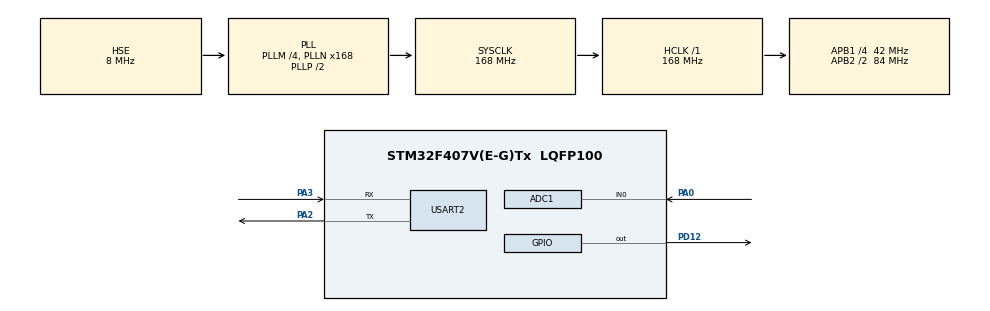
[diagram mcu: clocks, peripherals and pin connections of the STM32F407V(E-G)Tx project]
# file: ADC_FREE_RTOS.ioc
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ADC1.Channel-0\#ChannelRegularConversion=ADC_CHANNEL_0
ADC1.ClockPrescaler=ADC_CLOCK_SYNC_PCLK_DIV4
ADC1.NbrOfConversionFlag=1
ADC1.Rank-0\#ChannelRegularConversion=1
ADC1.Resolution=ADC_RESOLUTION_8B
ADC1.SamplingTime-0\#ChannelRegularConversion=ADC_SAMPLETIME_28CYCLES
ADC1.master=1
FREERTOS.BinarySemaphores01=BinSem,Dynamic,NULL
FREERTOS.Tasks01=LEDTask,0,128,LEDtask,Default,NULL,Dynamic,NULL,NULL;myADC,1,128,ADCTask,Default,NULL,Dynamic,NULL,NULL
Mcu.Family=STM32F4
Mcu.Name=STM32F407V(E-G)Tx
Mcu.Package=LQFP100
NVIC.PriorityGroup=NVIC_PRIORITYGROUP_4
NVIC.TIM1_UP_TIM10_IRQn=true\:0\:0\:false\:false\:true\:false\:false\:true
NVIC.TimeBase=TIM1_UP_TIM10_IRQn
NVIC.TimeBaseIP=TIM1
PA0-WKUP.Signal=ADCx_IN0
PA2.Mode=Asynchronous
PA2.Signal=USART2_TX
PA3.Mode=Asynchronous
PA3.Signal=USART2_RX
PD12.Signal=GPIO_Output
PH0-OSC_IN.Mode=HSE-External-Oscillator
PH0-OSC_IN.Signal=RCC_OSC_IN
PH1-OSC_OUT.Mode=HSE-External-Oscillator
PH1-OSC_OUT.Signal=RCC_OSC_OUT
ProjectManager.HeapSize=0x200
ProjectManager.StackSize=0x400
ProjectManager.TargetToolchain=STM32CubeIDE
RCC.48MHZClocksFreq_Value=84000000
RCC.AHBFreq_Value=168000000
RCC.APB1CLKDivider=RCC_HCLK_DIV4
RCC.APB1Freq_Value=42000000
RCC.APB1TimFreq_Value=84000000
RCC.APB2CLKDivider=RCC_HCLK_DIV2
RCC.APB2Freq_Value=84000000
RCC.APB2TimFreq_Value=168000000
RCC.CortexFreq_Value=168000000
RCC.HCLKFreq_Value=168000000
RCC.HSE_VALUE=8000000
RCC.HSI_VALUE=16000000
RCC.LSE_VALUE=32768
RCC.PLLM=4
RCC.PLLN=168
RCC.PLLSourceVirtual=RCC_PLLSOURCE_HSE
RCC.SYSCLKFreq_VALUE=168000000
RCC.SYSCLKSource=RCC_SYSCLKSOURCE_PLLCLK
RCC.VCOOutputFreq_Value=336000000
SH.ADCx_IN0.0=ADC1_IN0,IN0
USART2.VirtualMode=VM_ASYNC
VP_FREERTOS_VS_CMSIS_V1.Mode=CMSIS_V1
VP_SYS_VS_tim1.Mode=TIM1
board=custom

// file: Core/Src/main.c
/* USER CODE BEGIN Header */
/**
  ******************************************************************************
  * @file           : main.c
  * @brief          : Main program body
  ******************************************************************************
  * @attention
  *
  * <h2><center>&copy; Copyright (c) 2021 STMicroelectronics.
  * All rights reserved.</center></h2>
  *
  * This software component is licensed by ST under BSD 3-Clause license,
  * the "License"; You may not use this file except in compliance with the
  * License. You may obtain a copy of the License at:
  *                        opensource.org/licenses/BSD-3-Clause
  *
  ******************************************************************************
  */
/* USER CODE END Header */
#include "main.h"
#include "cmsis_os.h"

ADC_HandleTypeDef hadc1;

UART_HandleTypeDef huart2;

osThreadId LEDTaskHandle;
osThreadId myADCHandle;
osSemaphoreId BinSemHandle;

void SystemClock_Config(void);
static void MX_GPIO_Init(void);
static void MX_ADC1_Init(void);
static void MX_USART2_UART_Init(void);
void LEDtask(void const * argument);
void ADCTask(void const * argument);

/* USER CODE BEGIN PFP */
uint32_t adcVal0;
/* USER CODE END PFP */

int main(void)
{

  /* MCU Configuration--------------------------------------------------------*/

  /* Reset of all peripherals, Initializes the Flash interface and the Systick. */
  HAL_Init();

  /* Configure the system clock */
  SystemClock_Config();

  /* Initialize all configured peripherals */
  MX_GPIO_Init();
  MX_ADC1_Init();
  MX_USART2_UART_Init();

  /* Create the semaphores(s) */
  /* definition and creation of BinSem */
  osSemaphoreDef(BinSem);
  BinSemHandle = osSemaphoreCreate(osSemaphore(BinSem), 1);

  /* Create the thread(s) */
  /* definition and creation of LEDTask */
  osThreadDef(LEDTask, LEDtask, osPriorityNormal, 0, 128);
  LEDTaskHandle = osThreadCreate(osThread(LEDTask), NULL);

  /* definition and creation of myADC */
  osThreadDef(myADC, ADCTask, osPriorityAboveNormal, 0, 128);
  myADCHandle = osThreadCreate(osThread(myADC), NULL);

  /* Start scheduler */
  osKernelStart();

  /* We should never get here as control is now taken by the scheduler */
  /* Infinite loop */
  while (1)
  {

  }
}

void SystemClock_Config(void)
{
  RCC_OscInitTypeDef RCC_OscInitStruct = {0};
  RCC_ClkInitTypeDef RCC_ClkInitStruct = {0};

  /** Configure the main internal regulator output voltage
  */
  __HAL_RCC_PWR_CLK_ENABLE();
  __HAL_PWR_VOLTAGESCALING_CONFIG(PWR_REGULATOR_VOLTAGE_SCALE1);
  /** Initializes the RCC Oscillators according to the specified parameters
  * in the RCC_OscInitTypeDef structure.
  */
  RCC_OscInitStruct.OscillatorType = RCC_OSCILLATORTYPE_HSE;
  RCC_OscInitStruct.HSEState = RCC_HSE_ON;
  RCC_OscInitStruct.PLL.PLLState = RCC_PLL_ON;
  RCC_OscInitStruct.PLL.PLLSource = RCC_PLLSOURCE_HSE;
  RCC_OscInitStruct.PLL.PLLM = 4;
  RCC_OscInitStruct.PLL.PLLN = 168;
  RCC_OscInitStruct.PLL.PLLP = RCC_PLLP_DIV2;
  RCC_OscInitStruct.PLL.PLLQ = 4;
  if (HAL_RCC_OscConfig(&RCC_OscInitStruct) != HAL_OK)
  {
    Error_Handler();
  }
  /** Initializes the CPU, AHB and APB buses clocks
  */
  RCC_ClkInitStruct.ClockType = RCC_CLOCKTYPE_HCLK|RCC_CLOCKTYPE_SYSCLK
                              |RCC_CLOCKTYPE_PCLK1|RCC_CLOCKTYPE_PCLK2;
  RCC_ClkInitStruct.SYSCLKSource = RCC_SYSCLKSOURCE_PLLCLK;
  RCC_ClkInitStruct.AHBCLKDivider = RCC_SYSCLK_DIV1;
  RCC_ClkInitStruct.APB1CLKDivider = RCC_HCLK_DIV4;
  RCC_ClkInitStruct.APB2CLKDivider = RCC_HCLK_DIV2;

  if (HAL_RCC_ClockConfig(&RCC_ClkInitStruct, FLASH_LATENCY_5) != HAL_OK)
  {
    Error_Handler();
  }
}

static void MX_ADC1_Init(void)
{

  ADC_ChannelConfTypeDef sConfig = {0};

  /** Configure the global features of the ADC (Clock, Resolution, Data Alignment and number of conversion)
  */
  hadc1.Instance = ADC1;
  hadc1.Init.ClockPrescaler = ADC_CLOCK_SYNC_PCLK_DIV4;
  hadc1.Init.Resolution = ADC_RESOLUTION_8B;
  hadc1.Init.ScanConvMode = DISABLE;
  hadc1.Init.ContinuousConvMode = DISABLE;
  hadc1.Init.DiscontinuousConvMode = DISABLE;
  hadc1.Init.ExternalTrigConvEdge = ADC_EXTERNALTRIGCONVEDGE_NONE;
  hadc1.Init.ExternalTrigConv = ADC_SOFTWARE_START;
  hadc1.Init.DataAlign = ADC_DATAALIGN_RIGHT;
  hadc1.Init.NbrOfConversion = 1;
  hadc1.Init.DMAContinuousRequests = DISABLE;
  hadc1.Init.EOCSelection = ADC_EOC_SINGLE_CONV;
  if (HAL_ADC_Init(&hadc1) != HAL_OK)
  {
    Error_Handler();
  }
  /** Configure for the selected ADC regular channel its corresponding rank in the sequencer and its sample time.
  */
  sConfig.Channel = ADC_CHANNEL_0;
  sConfig.Rank = 1;
  sConfig.SamplingTime = ADC_SAMPLETIME_28CYCLES;
  if (HAL_ADC_ConfigChannel(&hadc1, &sConfig) != HAL_OK)
  {
    Error_Handler();
  }

}

static void MX_USART2_UART_Init(void)
{

  huart2.Instance = USART2;
  huart2.Init.BaudRate = 115200;
  huart2.Init.WordLength = UART_WORDLENGTH_8B;
  huart2.Init.StopBits = UART_STOPBITS_1;
  huart2.Init.Parity = UART_PARITY_NONE;
  huart2.Init.Mode = UART_MODE_TX_RX;
  huart2.Init.HwFlowCtl = UART_HWCONTROL_NONE;
  huart2.Init.OverSampling = UART_OVERSAMPLING_16;
  if (HAL_UART_Init(&huart2) != HAL_OK)
  {
    Error_Handler();
  }

}

static void MX_GPIO_Init(void)
{
  GPIO_InitTypeDef GPIO_InitStruct = {0};

  /* GPIO Ports Clock Enable */
  __HAL_RCC_GPIOH_CLK_ENABLE();
  __HAL_RCC_GPIOA_CLK_ENABLE();
  __HAL_RCC_GPIOD_CLK_ENABLE();

  /*Configure GPIO pin Output Level */
  HAL_GPIO_WritePin(GPIOD, GPIO_PIN_12, GPIO_PIN_RESET);

  /*Configure GPIO pin : PD12 */
  GPIO_InitStruct.Pin = GPIO_PIN_12;
  GPIO_InitStruct.Mode = GPIO_MODE_OUTPUT_PP;
  GPIO_InitStruct.Pull = GPIO_NOPULL;
  GPIO_InitStruct.Speed = GPIO_SPEED_FREQ_LOW;
  HAL_GPIO_Init(GPIOD, &GPIO_InitStruct);

}

void LEDtask(void const * argument)
{
  /* USER CODE BEGIN 5 */
  /* Infinite loop */
  for(;;)
  {
  char *str1= "Switch on and off LED Task\n";
  HAL_UART_Transmit(&huart2, (uint8_t *) str1,strlen(str1),100);
  HAL_GPIO_TogglePin(GPIOD, GPIO_PIN_12);

  osDelay(50);
  }
  /* USER CODE END 5 */
}

void ADCTask(void const * argument)
{
  /* USER CODE BEGIN ADCTask */
  /* Infinite loop */
  for(;;)
  {
	  //HAL_UART_Transmit(&huart2, (uint8_t *) str1,strlen(str1),100);

	  	  osSemaphoreWait(BinSemHandle, osWaitForever);

	  HAL_ADC_Start(&hadc1);
	 	  if(HAL_ADC_PollForConversion(&hadc1, 1000)== HAL_OK)
	 	  {
	 		  adcVal0=HAL_ADC_GetValue(&hadc1);
	 	  }
	 	 char *str2= "ADC is working \n";
	 	   HAL_UART_Transmit(&huart2, (uint8_t *) str2,strlen(str2),100);
	 	  HAL_UART_Transmit(&huart2, (uint32_t) adcVal0,sizeof(uint32_t),100);
	 	  osSemaphoreRelease(BinSemHandle);
    osDelay(50);
  }
  /* USER CODE END ADCTask */
}

 /**
  * @brief  Period elapsed callback in non blocking mode
  * @note   This function is called  when TIM1 interrupt took place, inside
  * HAL_TIM_IRQHandler(). It makes a direct call to HAL_IncTick() to increment
  * a global variable "uwTick" used as application time base.
  * @param  htim : TIM handle
  * @retval None
  */
void HAL_TIM_PeriodElapsedCallback(TIM_HandleTypeDef *htim)
{
  if (htim->Instance == TIM1) {
    HAL_IncTick();
  }
}

void Error_Handler(void)
{
  __disable_irq();
  while (1)
  {
  }
}

/************************ (C) COPYRIGHT STMicroelectronics *****END OF FILE****/
